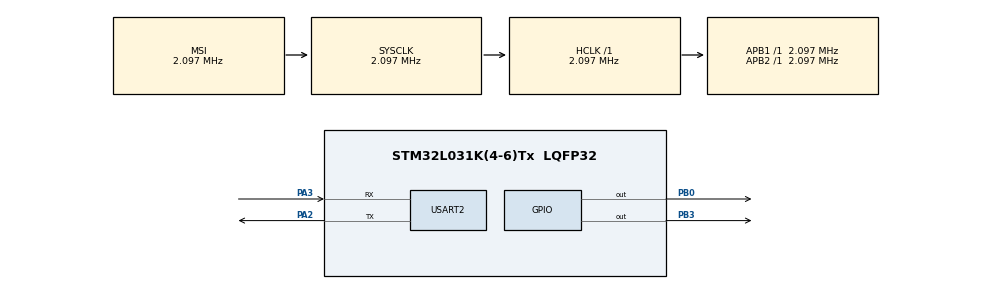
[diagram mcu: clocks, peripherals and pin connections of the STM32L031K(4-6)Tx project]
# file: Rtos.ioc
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FREERTOS.Tasks01=defaultTask,0,128,Task1,Default,NULL,Dynamic,NULL,NULL;myTask02,-3,128,Task2,Default,NULL,Dynamic,NULL,NULL;myTask03,-3,128,Task3,Default,NULL,Dynamic,NULL,NULL
Mcu.Family=STM32L0
Mcu.Name=STM32L031K(4-6)Tx
Mcu.Package=LQFP32
NVIC.TIM2_IRQn=true\:3\:0\:false\:false\:true\:false\:false\:true\:true
NVIC.TimeBase=TIM2_IRQn
NVIC.TimeBaseIP=TIM2
NVIC.USART2_IRQn=true\:3\:0\:false\:false\:true\:true\:true\:true\:true
PA2.Mode=Asynchronous
PA2.Signal=USART2_TX
PA3.Mode=Asynchronous
PA3.Signal=USART2_RX
PB0.Signal=GPIO_Output
PB3.Signal=GPIO_Output
PC14-OSC32_IN.Mode=LSE-External-Oscillator
PC14-OSC32_IN.Signal=RCC_OSC32_IN
PC15-OSC32_OUT.Mode=LSE-External-Oscillator
PC15-OSC32_OUT.Signal=RCC_OSC32_OUT
ProjectManager.HeapSize=0x200
ProjectManager.StackSize=0x400
ProjectManager.TargetToolchain=STM32CubeIDE
RCC.AHBFreq_Value=2097000
RCC.APB1Freq_Value=2097000
RCC.APB1TimFreq_Value=2097000
RCC.APB2Freq_Value=2097000
RCC.APB2TimFreq_Value=2097000
RCC.HSE_VALUE=8000000
RCC.HSI16_VALUE=16000000
RCC.HSI_VALUE=16000000
RCC.MSI_VALUE=2097000
RCC.SYSCLKFreq_VALUE=2097000
RCC.VCOOutputFreq_Value=48000000
USART2.VirtualMode-Asynchronous=VM_ASYNC
VP_FREERTOS_VS_CMSIS_V1.Mode=CMSIS_V1
VP_SYS_VS_tim2.Mode=TIM2
board=custom

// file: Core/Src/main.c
/* USER CODE BEGIN Header */
/**
  ******************************************************************************
  * @file           : main.c
  * @brief          : Main program body
  ******************************************************************************
  * @attention
  *
  * Copyright (c) 2022 STMicroelectronics.
  * All rights reserved.
  *
  * This software is licensed under terms that can be found in the LICENSE file
  * in the root directory of this software component.
  * If no LICENSE file comes with this software, it is provided AS-IS.
  *
  ******************************************************************************
  */
/* USER CODE END Header */
#include "main.h"
#include "cmsis_os.h"

 UART_HandleTypeDef huart2;

osThreadId defaultTaskHandle;
osThreadId myTask02Handle;
osThreadId myTask03Handle;

void SystemClock_Config(void);
static void MX_GPIO_Init(void);
static void MX_USART2_UART_Init(void);
void Task1(void const * argument);
void Task2(void const * argument);
void Task3(void const * argument);
void send_Task1(void);
void send_Task2(void);

int main(void)
{

  /* MCU Configuration--------------------------------------------------------*/

  /* Reset of all peripherals, Initializes the Flash interface and the Systick. */
  HAL_Init();

  /* Configure the system clock */
  SystemClock_Config();

  /* Initialize all configured peripherals */
  MX_GPIO_Init();
  MX_USART2_UART_Init();

  /* Create the thread(s) */
  /* definition and creation of defaultTask */
  osThreadDef(defaultTask, Task1, osPriorityNormal, 0, 128);
  defaultTaskHandle = osThreadCreate(osThread(defaultTask), NULL);

  /* definition and creation of myTask02 */
  osThreadDef(myTask02, Task2, osPriorityIdle, 0, 128);
  myTask02Handle = osThreadCreate(osThread(myTask02), NULL);

  /* definition and creation of myTask03 */
  osThreadDef(myTask03, Task3, osPriorityIdle, 0, 128);
  myTask03Handle = osThreadCreate(osThread(myTask03), NULL);

  /* Start scheduler */
 osKernelStart();

  /* We should never get here as control is now taken by the scheduler */
  /* Infinite loop */
  /* USER CODE BEGIN WHILE */
  while (1)
  {
	  send_Task1();
	  HAL_Delay(1000);
	  send_Task2();
	  HAL_Delay(1000);
    /* USER CODE END WHILE */

  }
}

void send_Task1(void)
{
	uint8_t data[] = "Hello From Task1\r\n";
	HAL_UART_Transmit(&huart2, data, sizeof(data), 100);
}
void send_Task2(void)
{
	uint8_t data[] = "Hello From Task2\r\n";
	HAL_UART_Transmit(&huart2, data, sizeof(data), 100);
}
void SystemClock_Config(void)
{
  RCC_OscInitTypeDef RCC_OscInitStruct = {0};
  RCC_ClkInitTypeDef RCC_ClkInitStruct = {0};
  RCC_PeriphCLKInitTypeDef PeriphClkInit = {0};

  /** Configure the main internal regulator output voltage
  */
  __HAL_PWR_VOLTAGESCALING_CONFIG(PWR_REGULATOR_VOLTAGE_SCALE1);

  /** Initializes the RCC Oscillators according to the specified parameters
  * in the RCC_OscInitTypeDef structure.
  */
  RCC_OscInitStruct.OscillatorType = RCC_OSCILLATORTYPE_MSI;
  RCC_OscInitStruct.MSIState = RCC_MSI_ON;
  RCC_OscInitStruct.MSICalibrationValue = 0;
  RCC_OscInitStruct.MSIClockRange = RCC_MSIRANGE_5;
  RCC_OscInitStruct.PLL.PLLState = RCC_PLL_NONE;
  if (HAL_RCC_OscConfig(&RCC_OscInitStruct) != HAL_OK)
  {
    Error_Handler();
  }

  /** Initializes the CPU, AHB and APB buses clocks
  */
  RCC_ClkInitStruct.ClockType = RCC_CLOCKTYPE_HCLK|RCC_CLOCKTYPE_SYSCLK
                              |RCC_CLOCKTYPE_PCLK1|RCC_CLOCKTYPE_PCLK2;
  RCC_ClkInitStruct.SYSCLKSource = RCC_SYSCLKSOURCE_MSI;
  RCC_ClkInitStruct.AHBCLKDivider = RCC_SYSCLK_DIV1;
  RCC_ClkInitStruct.APB1CLKDivider = RCC_HCLK_DIV1;
  RCC_ClkInitStruct.APB2CLKDivider = RCC_HCLK_DIV1;

  if (HAL_RCC_ClockConfig(&RCC_ClkInitStruct, FLASH_LATENCY_0) != HAL_OK)
  {
    Error_Handler();
  }
  PeriphClkInit.PeriphClockSelection = RCC_PERIPHCLK_USART2;
  PeriphClkInit.Usart2ClockSelection = RCC_USART2CLKSOURCE_PCLK1;
  if (HAL_RCCEx_PeriphCLKConfig(&PeriphClkInit) != HAL_OK)
  {
    Error_Handler();
  }
}

static void MX_USART2_UART_Init(void)
{

  huart2.Instance = USART2;
  huart2.Init.BaudRate = 115200;
  huart2.Init.WordLength = UART_WORDLENGTH_8B;
  huart2.Init.StopBits = UART_STOPBITS_1;
  huart2.Init.Parity = UART_PARITY_NONE;
  huart2.Init.Mode = UART_MODE_TX_RX;
  huart2.Init.HwFlowCtl = UART_HWCONTROL_NONE;
  huart2.Init.OverSampling = UART_OVERSAMPLING_16;
  huart2.Init.OneBitSampling = UART_ONE_BIT_SAMPLE_DISABLE;
  huart2.AdvancedInit.AdvFeatureInit = UART_ADVFEATURE_NO_INIT;
  if (HAL_UART_Init(&huart2) != HAL_OK)
  {
    Error_Handler();
  }

}

static void MX_GPIO_Init(void)
{
  GPIO_InitTypeDef GPIO_InitStruct = {0};

  /* GPIO Ports Clock Enable */
  __HAL_RCC_GPIOC_CLK_ENABLE();
  __HAL_RCC_GPIOA_CLK_ENABLE();
  __HAL_RCC_GPIOB_CLK_ENABLE();

  /*Configure GPIO pin Output Level */
  HAL_GPIO_WritePin(GPIOB, GPIO_PIN_0|GPIO_PIN_3, GPIO_PIN_RESET);

  /*Configure GPIO pins : PB0 PB3 */
  GPIO_InitStruct.Pin = GPIO_PIN_0|GPIO_PIN_3;
  GPIO_InitStruct.Mode = GPIO_MODE_OUTPUT_PP;
  GPIO_InitStruct.Pull = GPIO_NOPULL;
  GPIO_InitStruct.Speed = GPIO_SPEED_FREQ_LOW;
  HAL_GPIO_Init(GPIOB, &GPIO_InitStruct);

}

void Task1(void const * argument)
{
  /* USER CODE BEGIN 5 */
  /* Infinite loop */
  for(;;)
  {
    send_Task1();
    osDelay(1000);
  }
  /* USER CODE END 5 */
}

void Task2(void const * argument)
{
  /* USER CODE BEGIN Task2 */
  /* Infinite loop */
  for(;;)
  {
	    send_Task2();
	    osDelay(1000);
  }
  /* USER CODE END Task2 */
}

void Task3(void const * argument)
{
  for(;;)
  {
    osDelay(1);
  }
}

void HAL_TIM_PeriodElapsedCallback(TIM_HandleTypeDef *htim)
{
  if (htim->Instance == TIM2) {
    HAL_IncTick();
  }
}

void Error_Handler(void)
{
  __disable_irq();
  while (1)
  {
  }
}
